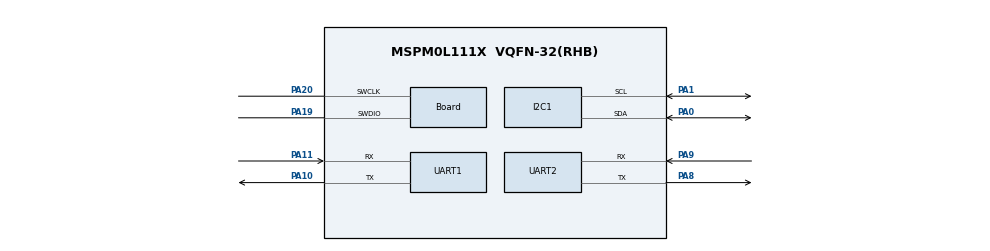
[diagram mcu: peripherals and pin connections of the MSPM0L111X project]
/**
 * @cliArgs --device "MSPM0L111X" --part "Default" --package "VQFN-32(RHB)" --product "mspm0_sdk@2.07.00.06"
 * @versions {"tool":"1.25.0+4268"}
 */

/**
 * Import the modules used in this configuration.
 */
const GPIO   = scripting.addModule("/ti/driverlib/GPIO", {}, false);
const GPIO1  = GPIO.addInstance();
const GPIO2  = GPIO.addInstance();
const GPIO3  = GPIO.addInstance();
const I2C    = scripting.addModule("/ti/driverlib/I2C", {}, false);
const I2C1   = I2C.addInstance();
const SYSCTL = scripting.addModule("/ti/driverlib/SYSCTL");
const UART   = scripting.addModule("/ti/driverlib/UART", {}, false);
const UART1  = UART.addInstance();
const UART2  = UART.addInstance();

/**
 * Write custom configuration values to the imported modules.
 */
GPIO1.$name                         = "CONFIG_GPIO_LPn";
GPIO1.port                          = "PORTA";
GPIO1.associatedPins[0].assignedPin = "5";
GPIO1.associatedPins[0].$name       = "PIN_A5";

const Board                       = scripting.addModule("/ti/driverlib/Board", {}, false);
Board.peripheral.$assign          = "DEBUGSS";
Board.peripheral.swclkPin.$assign = "PA20";
Board.peripheral.swdioPin.$assign = "PA19";

GPIO2.$name                          = "CONFIG_GPIO_I2C_RST";
GPIO2.port                           = "PORTA";
GPIO2.associatedPins[0].initialValue = "SET";
GPIO2.associatedPins[0].$name        = "PIN_A24";
GPIO2.associatedPins[0].assignedPin  = "24";

GPIO3.$name                         = "CONFIG_GPIO_INT";
GPIO3.port                          = "PORTA";
GPIO3.associatedPins[0].direction   = "INPUT";
GPIO3.associatedPins[0].$name       = "PIN_A26";
GPIO3.associatedPins[0].assignedPin = "26";

I2C1.$name                             = "CONFIG_I2C_0";
I2C1.advDigitalGlitchFilter            = "CLOCKS_1";
I2C1.advControllerRXFIFOTRIG           = "BYTES_8";
I2C1.advControllerTXFIFOTRIG           = "BYTES_7";
I2C1.enableDMAEvent1                   = false;
I2C1.enableDMAEvent2                   = false;
I2C1.basicEnableController             = true;
I2C1.peripheral.$assign                = "I2C0";
I2C1.peripheral.sdaPin.$assign         = "PA0";
I2C1.peripheral.sclPin.$assign         = "PA1";
I2C1.sdaPinConfig.$name                = "ti_driverlib_gpio_GPIOPinGeneric0";
I2C1.sdaPinConfig.hideOutputInversion  = scripting.forceWrite(false);
I2C1.sdaPinConfig.onlyInternalResistor = scripting.forceWrite(false);
I2C1.sdaPinConfig.passedPeripheralType = scripting.forceWrite("Digital");
I2C1.sclPinConfig.$name                = "ti_driverlib_gpio_GPIOPinGeneric1";
I2C1.sclPinConfig.hideOutputInversion  = scripting.forceWrite(false);
I2C1.sclPinConfig.onlyInternalResistor = scripting.forceWrite(false);
I2C1.sclPinConfig.passedPeripheralType = scripting.forceWrite("Digital");

SYSCTL.EXCLKDivider = "8";

UART1.$name                            = "CONFIG_UART_0";
UART1.targetBaudRate                   = 921600;
UART1.peripheral.$assign               = "UART0";
UART1.peripheral.rxPin.$assign         = "PA11";
UART1.peripheral.txPin.$assign         = "PA10";
UART1.txPinConfig.$name                = "ti_driverlib_gpio_GPIOPinGeneric2";
UART1.txPinConfig.direction            = scripting.forceWrite("OUTPUT");
UART1.txPinConfig.hideOutputInversion  = scripting.forceWrite(false);
UART1.txPinConfig.onlyInternalResistor = scripting.forceWrite(false);
UART1.txPinConfig.passedPeripheralType = scripting.forceWrite("Digital");
UART1.rxPinConfig.$name                = "ti_driverlib_gpio_GPIOPinGeneric3";
UART1.rxPinConfig.hideOutputInversion  = scripting.forceWrite(false);
UART1.rxPinConfig.onlyInternalResistor = scripting.forceWrite(false);
UART1.rxPinConfig.passedPeripheralType = scripting.forceWrite("Digital");

UART2.$name                            = "CONFIG_UART_1";
UART2.targetBaudRate                   = 115200;
UART2.peripheral.$assign               = "UART1";
UART2.peripheral.rxPin.$assign         = "PA9";
UART2.peripheral.txPin.$assign         = "PA8";
UART2.txPinConfig.$name                = "ti_driverlib_gpio_GPIOPinGeneric4";
UART2.txPinConfig.direction            = scripting.forceWrite("OUTPUT");
UART2.txPinConfig.hideOutputInversion  = scripting.forceWrite(false);
UART2.txPinConfig.onlyInternalResistor = scripting.forceWrite(false);
UART2.txPinConfig.passedPeripheralType = scripting.forceWrite("Digital");
UART2.rxPinConfig.$name                = "ti_driverlib_gpio_GPIOPinGeneric5";
UART2.rxPinConfig.hideOutputInversion  = scripting.forceWrite(false);
UART2.rxPinConfig.onlyInternalResistor = scripting.forceWrite(false);
UART2.rxPinConfig.passedPeripheralType = scripting.forceWrite("Digital");

const ProjectConfig              = scripting.addModule("/ti/project_config/ProjectConfig", {}, false);
ProjectConfig.migrationCondition = true;

/**
 * Pinmux solution for unlocked pins/peripherals. This ensures that minor changes to the automatic solver in a future
 * version of the tool will not impact the pinmux you originally saw.  These lines can be completely deleted in order to
 * re-solve from scratch.
 */
GPIO1.associatedPins[0].pin.$suggestSolution = "PA5";
GPIO2.associatedPins[0].pin.$suggestSolution = "PA24";
GPIO3.associatedPins[0].pin.$suggestSolution = "PA26";
SYSCTL.peripheral.$suggestSolution           = "SYSCTL";
